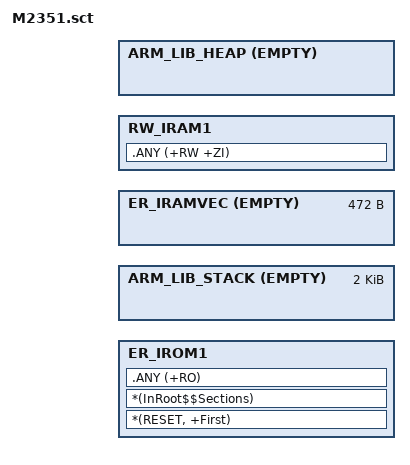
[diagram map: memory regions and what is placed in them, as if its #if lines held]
#! armcc -E

#include "partition_M2351_sub.h"

/* Check relevant macros have been defined */
#if (! defined(NU_TZ_SECURE_FLASH_SIZE))
#error("NU_TZ_SECURE_FLASH_SIZE not defined")
#endif
#if (! defined(NU_TZ_SECURE_SRAM_SIZE))
#error("NU_TZ_SECURE_SRAM_SIZE not defined")
#endif
#if (! defined(NU_TZ_NSC_REGION_SIZE))
#error("NU_TZ_NSC_REGION_SIZE not defined")
#endif

/* Requirements for NSC location
 *
 * 1. By IDAU, 0~0x4000 is secure. NSC can only locate in 0x4000~0x10000000.
 * 2. Greentea flash IAP uses last 4 sectors for its test. Avoid this range.
 * 3. Greentea NVSTORE uses last 2 sectors or 4KB x 2 for its test. Avoid this range.
 */
#define NU_TZ_NSC_REGION_BASE       (MBED_APP_START + MBED_APP_SIZE - 0x2000 - NU_TZ_NSC_REGION_SIZE)

/* Initial/ISR stack size */
#if (! defined(NU_INITIAL_STACK_SIZE))
#if defined(__DOMAIN_NS) && __DOMAIN_NS
#define NU_INITIAL_STACK_SIZE       0x800
#else
#define NU_INITIAL_STACK_SIZE       0x800
#endif
#endif

#if defined(__DOMAIN_NS) && __DOMAIN_NS

#if (! defined(MBED_APP_START))
#define MBED_APP_START              (0x10000000 + NU_TZ_SECURE_FLASH_SIZE)
#endif

#if (! defined(MBED_APP_SIZE))
#define MBED_APP_SIZE               (0x80000 - NU_TZ_SECURE_FLASH_SIZE)
#endif

LR_IROM1    MBED_APP_START
{
    /* load address = execution address */
    ER_IROM1    +0
    {
        *(RESET, +First)
        *(InRoot$$Sections)
        .ANY (+RO)
    }

    ARM_LIB_STACK   0x30000000 + NU_TZ_SECURE_SRAM_SIZE     EMPTY   NU_INITIAL_STACK_SIZE
    {
    }

    /* Reserve for vectors
     *
     * Vector table base address is required to be 128-byte aligned at a minimum.
     * A PE might impose further restrictions on it. */
    ER_IRAMVEC  AlignExpr(+0, 128)  EMPTY   (4*(16 + 102))
    {
    }

    /* 16 byte-aligned */
    RW_IRAM1    AlignExpr(+0, 16)
    {
        .ANY (+RW +ZI)
    }

    ARM_LIB_HEAP    AlignExpr(+0, 16) EMPTY (0x30018000 - AlignExpr(ImageLimit(RW_IRAM1), 16))
    {
    }
}

ScatterAssert(LoadLimit(LR_IROM1) <= (MBED_APP_START + MBED_APP_SIZE))
ScatterAssert(ImageLimit(ARM_LIB_HEAP) <= 0x30018000)

#else

#if (! defined(MBED_APP_START))
#define MBED_APP_START              0
#endif

#if (! defined(MBED_APP_SIZE))
#define MBED_APP_SIZE               NU_TZ_SECURE_FLASH_SIZE
#endif

LR_IROM1 MBED_APP_START
{
    /* load address = execution address */
    ER_IROM1    +0
    {
        *(RESET, +First)
        *(InRoot$$Sections)
        .ANY (+RO)
    }

    ARM_LIB_STACK   0x20000000  EMPTY   NU_INITIAL_STACK_SIZE
    {
    }

    /* Reserve for vectors
     *
     * Vector table base address is required to be 128-byte aligned at a minimum.
     * A PE might impose further restrictions on it. */
    ER_IRAMVEC  AlignExpr(+0, 128)  EMPTY   (4*(16 + 102))
    {
    }

    /* 16 byte-aligned */
    RW_IRAM1    AlignExpr(+0, 16)
    {
        .ANY (+RW +ZI)
    }

    ARM_LIB_HEAP    AlignExpr(+0, 16) EMPTY (0x20000000 + NU_TZ_SECURE_SRAM_SIZE - AlignExpr(ImageLimit(RW_IRAM1), 16))
    {
    }
}

LR_IROM2 NU_TZ_NSC_REGION_BASE
{
    NSC_ROM +0  NU_TZ_NSC_REGION_SIZE  
    {
        *(Veneer$$CMSE)
    }
}

ScatterAssert(LoadLimit(LR_IROM1) <= NU_TZ_NSC_REGION_BASE)
ScatterAssert(LoadLimit(LR_IROM2) <= (NU_TZ_NSC_REGION_BASE + NU_TZ_NSC_REGION_SIZE))
/* By IDAU, 0~0x4000 is secure. NSC can only locate in 0x4000~0x10000000 */
ScatterAssert(LoadBase(LR_IROM2) >= 0x4000)
ScatterAssert(ImageLimit(ARM_LIB_HEAP) <= (0x20000000 + NU_TZ_SECURE_SRAM_SIZE))

#endif
